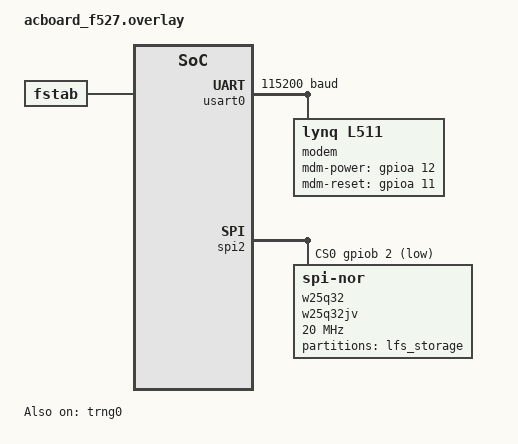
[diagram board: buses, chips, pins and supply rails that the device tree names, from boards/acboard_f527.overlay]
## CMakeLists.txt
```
cmake_minimum_required(VERSION 3.20.0)

find_package(Zephyr REQUIRED HINTS $ENV{ZEPHYR_BASE})
project(l511c_bringup LANGUAGES C CXX)

# === C sources ===
target_sources(app PRIVATE src/main.c)

# === C++ OCPP bridge ===
set_source_files_properties(src/ocpp_bridge.cpp PROPERTIES LANGUAGE CXX)
target_sources(app PRIVATE src/ocpp_bridge.cpp)

# === C++ STL headers (overrides picolibc's -nostdinc++) ===
# Zephyr SDK's full C++ STL is available but blocked by -nostdinc++
# We add the include paths explicitly for C++ files only
get_filename_component(GNU_BINDIR ${CMAKE_CXX_COMPILER} DIRECTORY)
get_filename_component(GNU_PREFIX ${GNU_BINDIR} DIRECTORY)
set(SDK_SYSROOT ${GNU_PREFIX}/arm-zephyr-eabi)
set(CXX_HEADER_ROOT ${SDK_SYSROOT}/include/c++/14.3.0)
# Target-specific C++ headers (c++config.h etc.)
execute_process(COMMAND ${CMAKE_CXX_COMPILER} -mcpu=cortex-m33 -mthumb -mfp16-format=ieee -print-multi-directory
  OUTPUT_VARIABLE MULTI_DIR OUTPUT_STRIP_TRAILING_WHITESPACE)
target_include_directories(app SYSTEM PRIVATE
  $<$<COMPILE_LANGUAGE:CXX>:${CXX_HEADER_ROOT}>
  $<$<COMPILE_LANGUAGE:CXX>:${CXX_HEADER_ROOT}/${MULTI_DIR}>
  $<$<COMPILE_LANGUAGE:CXX>:${CXX_HEADER_ROOT}/arm-zephyr-eabi/${MULTI_DIR}>
)

# Link C++ standard library (MicroOcpp needs std::string, new/delete, static ctors)
zephyr_link_libraries(stdc++ supc++)

# === MicroOcpp ===
file(GLOB_RECURSE MO_SOURCES
  ${CMAKE_CURRENT_SOURCE_DIR}/lib/MicroOcpp/src/*.cpp
  ${CMAKE_CURRENT_SOURCE_DIR}/lib/MicroOcpp/src/*.c
)
# Exclude files that need mbedTLS directly, or conflict with our adapter
list(FILTER MO_SOURCES EXCLUDE REGEX "FtpMbedTLS|CertificateMbedTLS|CertificateService|Platform\\.cpp")

foreach(src ${MO_SOURCES})
  set_source_files_properties(${src} PROPERTIES LANGUAGE CXX)
  target_sources(app PRIVATE ${src})
endforeach()

# === Include paths ===
target_include_directories(app PRIVATE
  ${CMAKE_CURRENT_SOURCE_DIR}/lib/MicroOcpp/src
  ${CMAKE_CURRENT_SOURCE_DIR}/lib/ArduinoJson/src
  ${CMAKE_CURRENT_SOURCE_DIR}/src
)

# === Build flags for MicroOcpp ===
target_compile_definitions(app PRIVATE
  MO_CUSTOM_WS
  MO_CUSTOM_CONSOLE
  MO_CUSTOM_TIMER
  MO_CUSTOM_RNG
  MO_PLATFORM=0
  MO_ENABLE_V201
  MO_OVERRIDE_ALLOCATION=1
  MO_CUSTOM_CONSOLE_MAXMSGSIZE=512
)
```

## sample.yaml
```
sample:
  description: ACBoard L511C WSS OCPP bring-up
  name: ACBoard L511C WSS OCPP bring-up
common:
  platform_allow:
    - acboard_f527
  tags:
    - modem
    - ocpp
    - websocket
tests:
  sample.boards.acboard.l511c_bringup:
    depends_on:
      - gpio
      - serial
    filter: dt_chosen_enabled("zephyr,modem-uart")
```

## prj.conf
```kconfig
# ============================================
# L511C OCPP on WSS (WebSocket Secure / TLS)
# GD32E513 + MicroOcpp + mbedTLS
# ============================================

# --- GPIO & Serial ---
CONFIG_GPIO=y
CONFIG_SERIAL=y
CONFIG_UART_INTERRUPT_DRIVEN=y
CONFIG_UART_ASYNC_API=y
CONFIG_CONSOLE=y
CONFIG_UART_CONSOLE=y
CONFIG_PRINTK=y

# --- Memory ---
CONFIG_HEAP_MEM_POOL_SIZE=24576
CONFIG_MAIN_STACK_SIZE=6144
CONFIG_SYSTEM_WORKQUEUE_STACK_SIZE=4096
CONFIG_NET_MGMT_EVENT_STACK_SIZE=2048

# --- Networking (native IP stack) ---
CONFIG_NETWORKING=y
CONFIG_NET_NATIVE=y
CONFIG_NET_IPV4=y
CONFIG_NET_IF_UNICAST_IPV4_ADDR_COUNT=2
CONFIG_NET_TCP=y
CONFIG_NET_UDP=y
CONFIG_NET_SOCKETS=y
CONFIG_DNS_RESOLVER=y
CONFIG_NET_SOCKETS_DNS_TIMEOUT=12000
CONFIG_NET_SOCKETS_CONNECT_TIMEOUT=15000
CONFIG_NET_CONTEXT_RCVTIMEO=y

# --- PPP L2 ---
CONFIG_NET_L2_PPP=y
CONFIG_NET_L2_PPP_OPTION_DNS_USE=y
CONFIG_NET_L2_PPP_PAP=y
CONFIG_NET_L2_PPP_PAP_USERNAME="cmnet"
CONFIG_NET_L2_PPP_PAP_PASSWORD="cmnet"
CONFIG_NET_L2_PPP_MGMT=y

# --- Modem (lynq,l511 driver powers the module and brings up PPP) ---
CONFIG_NET_MGMT=y
CONFIG_NET_MGMT_EVENT=y
CONFIG_NET_CONNECTION_MANAGER=y
CONFIG_MODEM_LYNQ_L511=y

# --- HTTP & WebSocket Client (WSS / TLS) ---
CONFIG_HTTP_CLIENT=y
CONFIG_WEBSOCKET_CLIENT=y
CONFIG_WEBSOCKET_MAX_CONTEXTS=1

# mbedTLS
CONFIG_MBEDTLS=y
CONFIG_MBEDTLS_ENABLE_HEAP=y
CONFIG_MBEDTLS_HEAP_SIZE=24576
CONFIG_MBEDTLS_SSL_IN_CONTENT_LEN=3072
CONFIG_MBEDTLS_SSL_OUT_CONTENT_LEN=3072
CONFIG_MBEDTLS_SSL_PROTO_TLS1_2=y
CONFIG_MBEDTLS_CIPHERSUITE_TLS_ECDHE_RSA_WITH_AES_128_GCM_SHA256=y
CONFIG_MBEDTLS_CIPHERSUITE_TLS_ECDHE_ECDSA_WITH_AES_128_GCM_SHA256=y
CONFIG_PSA_WANT_KEY_TYPE_RSA_PUBLIC_KEY=y
CONFIG_PSA_WANT_ALG_SHA_1=y

# TLS Socket (mTLS)
CONFIG_NET_SOCKETS_SOCKOPT_TLS=y
CONFIG_NET_SOCKETS_TLS_MAX_CONTEXTS=1
CONFIG_NET_SOCKETS_TLS_CERT_VERIFY_CALLBACK=y

# SNTP time sync (required for TLS cert verification)
CONFIG_SNTP=y

# --- Network buffers ---
CONFIG_NET_BUF_RX_COUNT=30
CONFIG_NET_BUF_TX_COUNT=30
CONFIG_NET_BUF_DATA_SIZE=256

# --- Logging (immediate mode, ERR only, enable net_sock_tls ERR) ---
CONFIG_LOG=y
CONFIG_NET_LOG=y
CONFIG_LOG_DEFAULT_LEVEL=1
CONFIG_LOG_MODE_IMMEDIATE=y
CONFIG_MODEM_LYNQ_L511_LOG_LEVEL_INF=y
CONFIG_NET_SOCKETS_LOG_LEVEL_ERR=y

# --- Random (GD32F527 hardware TRNG seeds a xoshiro PRNG) ---
CONFIG_ENTROPY_GENERATOR=y
CONFIG_ENTROPY_GD32_TRNG=y
CONFIG_XOSHIRO_RANDOM_GENERATOR=y

# --- POSIX ---
CONFIG_POSIX_API=y

# --- C++ support ---
CONFIG_CPP=y

# --- LittleFS filesystem (external SPI NOR flash) ---
CONFIG_SPI=y
CONFIG_SPI_GD32_DMA=y
CONFIG_SPI_NOR=y
CONFIG_FLASH=y
CONFIG_FLASH_MAP=y
CONFIG_FILE_SYSTEM=y
CONFIG_FILE_SYSTEM_LITTLEFS=y
CONFIG_FS_LITTLEFS_FMP_DEV=y
```

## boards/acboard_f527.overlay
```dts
/*
 * Copyright (c) 2026
 * SPDX-License-Identifier: Apache-2.0
 */

#include <zephyr/dt-bindings/gpio/gpio.h>
#include <zephyr/dt-bindings/dma/gd32_dma.h>

/ {
	fstab {
		compatible = "zephyr,fstab";
		lfs1: lfs1 {
			compatible = "zephyr,fstab,littlefs";
			mount-point = "/lfs1";
			partition = <&lfs_part>;
			automount;
			read-size = <256>;
			prog-size = <256>;
			cache-size = <256>;
			lookahead-size = <128>;
			block-cycles = <512>;
		};
	};
};

/* Hardware TRNG: entropy for mbedTLS / the network stack. */
&trng0 {
	status = "okay";
};

&usart0 {
	status = "okay";
	current-speed = <115200>;
	pinctrl-0 = <&usart0_default>;
	pinctrl-names = "default";
	dmas = <&dma1 2 4 GD32_DMA_PRIORITY_VERY_HIGH 3>,
	       <&dma1 7 4 GD32_DMA_PRIORITY_HIGH 3>;
	dma-names = "rx", "tx";

	modem: l511 {
		compatible = "lynq,l511";
		mdm-power-gpios = <&gpioa 12 GPIO_ACTIVE_HIGH>;
		mdm-reset-gpios = <&gpioa 11 GPIO_ACTIVE_HIGH>;
		reset-pulse-ms = <200>;
		at-ready-delay-ms = <5000>;
	};
};

&spi2 {
	status = "okay";
	cs-gpios = <&gpiob 2 GPIO_ACTIVE_LOW>;
	pinctrl-0 = <&spi2_default>;
	pinctrl-names = "default";
	dmas = <&dma0 2 0 GD32_DMA_PRIORITY_HIGH 3>,
	       <&dma0 5 0 GD32_DMA_PRIORITY_MEDIUM 3>;
	dma-names = "rx", "tx";

	w25q32: w25q32jv@0 {
		compatible = "jedec,spi-nor";
		reg = <0>;
		spi-max-frequency = <20000000>;
		jedec-id = [c8 40 16];
		size = <33554432>;
	};
};

&w25q32 {
	partitions {
		compatible = "fixed-partitions";
		#address-cells = <1>;
		#size-cells = <1>;
		lfs_part: partition@0 {
			label = "lfs_storage";
			reg = <0x00000000 0x00400000>;
		};
	};
};
```

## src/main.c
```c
/*
 * Copyright (c) 2026
 * SPDX-License-Identifier: Apache-2.0
 *
 * L511C OCPP over WSS (WebSocket Secure / TLS with mTLS) on ACBoard.
 *
 * The cellular modem bring-up (power, AT init, dial, PPP) is handled by the
 * lynq,l511 driver, which brings up the PPP network interface. This app waits
 * for connectivity, opens a mutually-authenticated TLS WebSocket to the OCPP
 * server, and hands the socket to the OCPP bridge.
 */

#include <errno.h>
#include <stdio.h>
#include <string.h>

#include <zephyr/device.h>
#include <zephyr/kernel.h>
#include <zephyr/net/net_event.h>
#include <zephyr/net/net_if.h>
#include <zephyr/net/net_ip.h>
#include <zephyr/net/net_mgmt.h>
#include <zephyr/net/ppp.h>
#include <zephyr/net/socket.h>
#include <zephyr/net/sntp.h>
#include <zephyr/net/tls_credentials.h>
#include <zephyr/net/websocket.h>
#include <zephyr/logging/log.h>

#include <mbedtls/x509.h>
#include <mbedtls/x509_crt.h>

#include "tls_certificates.h"
#include "ocpp_bridge.h"

LOG_MODULE_REGISTER(l511c, LOG_LEVEL_INF);

/* OCPP server (WSS / TLS) */
#define OCPP_SERVER_HOST  "47.111.208.192"
#define OCPP_SERVER_PORT  "6669"
#define OCPP_SERVER_PATH  "/ocppj/812345678"
#define OCPP_CHARGEBOX_ID "812345678"

/* WS temp buffer (used during handshake) */
#define WS_TEMP_BUF_LEN  1024

/* PPP / connectivity events */
#define PPP_EVENT_CONNECTED     BIT(0)
#define PPP_EVENT_DISCONNECTED  BIT(1)
#define PPP_EVENT_DNS_READY     BIT(2)

/* The lynq,l511 driver owns the modem and creates the PPP interface, which is
 * the only (default) network interface.
 */
#define CELL_IFACE net_if_get_default()
K_EVENT_DEFINE(ppp_events);

/* ===== Net mgmt handlers ===== */

static void l4_event_handler(uint64_t event, struct net_if *iface,
			     void *info, size_t info_length, void *user_data)
{
	ARG_UNUSED(info); ARG_UNUSED(info_length); ARG_UNUSED(user_data);
	if (iface != CELL_IFACE) { return; }
	switch (event) {
	case NET_EVENT_L4_CONNECTED:
		k_event_clear(&ppp_events, PPP_EVENT_DISCONNECTED);
		k_event_post(&ppp_events, PPP_EVENT_CONNECTED);
		break;
	case NET_EVENT_DNS_SERVER_ADD:
	case NET_EVENT_DNS_SERVERS_RECONFIGURED: k_event_post(&ppp_events, PPP_EVENT_DNS_READY); break;
	case NET_EVENT_L4_DISCONNECTED:
		k_event_clear(&ppp_events, PPP_EVENT_CONNECTED | PPP_EVENT_DNS_READY);
		k_event_post(&ppp_events, PPP_EVENT_DISCONNECTED);
		break;
	}
}
NET_MGMT_REGISTER_EVENT_HANDLER(ppp_l4, NET_EVENT_L4_CONNECTED |
	NET_EVENT_L4_DISCONNECTED | NET_EVENT_DNS_SERVER_ADD |
	NET_EVENT_DNS_SERVERS_RECONFIGURED, l4_event_handler, NULL);

static void ppp_event_handler(uint64_t event, struct net_if *iface,
			      void *info, size_t info_length, void *user_data)
{
	ARG_UNUSED(info); ARG_UNUSED(info_length); ARG_UNUSED(user_data);
	if (iface != CELL_IFACE) { return; }
	switch (event) {
	case NET_EVENT_PPP_PHASE_DEAD:   LOG_DBG("ppp: DEAD"); break;
	case NET_EVENT_PPP_PHASE_RUNNING: LOG_DBG("ppp: RUN"); break;
	case NET_EVENT_PPP_CARRIER_ON:   LOG_INF("ppp: carrier on"); break;
	case NET_EVENT_PPP_CARRIER_OFF:
		LOG_INF("ppp: carrier off");
		k_event_clear(&ppp_events, PPP_EVENT_CONNECTED | PPP_EVENT_DNS_READY);
		k_event_post(&ppp_events, PPP_EVENT_DISCONNECTED);
		break;
	}
}
NET_MGMT_REGISTER_EVENT_HANDLER(ppp_phase, NET_EVENT_PPP_PHASE_DEAD |
	NET_EVENT_PPP_PHASE_RUNNING | NET_EVENT_PPP_CARRIER_ON |
	NET_EVENT_PPP_CARRIER_OFF, ppp_event_handler, NULL);

/* ===== WSS connect (TLS + mTLS) ===== */

/* TLS verify callback: skip CN/SAN hostname check since server cert has no CN */
static int tls_verify_cb(void *data, mbedtls_x509_crt *crt, int depth, uint32_t *flags)
{
	ARG_UNUSED(data); ARG_UNUSED(crt); ARG_UNUSED(depth);
	*flags &= ~MBEDTLS_X509_BADCERT_CN_MISMATCH;
	return 0;
}

static uint8_t ws_temp_buf[WS_TEMP_BUF_LEN];

static int tls_credential_add_once(sec_tag_t tag,
				   enum tls_credential_type type,
				   const void *cred, size_t credlen)
{
	int ret = tls_credential_add(tag, type, cred, credlen);

	return ret == -EEXIST ? 0 : ret;
}

static int ws_connect(void)
{
	struct zsock_addrinfo hints = { .ai_family = AF_INET, .ai_socktype = SOCK_STREAM };
	struct zsock_addrinfo *ai = NULL;
	struct sockaddr_in peer = {0};
	struct websocket_request req;
	char addr[NET_IPV4_ADDR_LEN];
	sec_tag_t sec_tags[] = { CA_CERTIFICATE_TAG, CLIENT_CERT_TAG };
	int sock = -1, ws_fd = -1, ret;

	/* Register certificates for mTLS */
	ret = tls_credential_add_once(CA_CERTIFICATE_TAG, TLS_CREDENTIAL_CA_CERTIFICATE,
				      ca_certificate, sizeof(ca_certificate));
	if (ret < 0) { LOG_ERR("CA cert add err: %d", ret); return ret; }
	LOG_DBG("CA cert ok (tag=%d)", CA_CERTIFICATE_TAG);

	ret = tls_credential_add_once(CLIENT_CERT_TAG, TLS_CREDENTIAL_PUBLIC_CERTIFICATE,
				      client_certificate, sizeof(client_certificate));
	if (ret < 0) { LOG_ERR("Client cert add err: %d", ret); return ret; }

	ret = tls_credential_add_once(CLIENT_CERT_TAG, TLS_CREDENTIAL_PRIVATE_KEY,
				      client_private_key, sizeof(client_private_key));
	if (ret < 0) { LOG_ERR("Client key add err: %d", ret); return ret; }
	LOG_DBG("Client cert+key ok (tag=%d)", CLIENT_CERT_TAG);

	/* Sync time for cert validity check */
	{
		struct sntp_time sntp_ts;
		struct timespec ts;
		LOG_DBG("SNTP ...");
		ret = sntp_simple("203.107.6.88", 5000, &sntp_ts);
		if (ret < 0) { ret = sntp_simple("ntp.aliyun.com", 8000, &sntp_ts); }
		if (ret >= 0) {
			ts.tv_sec = (time_t)sntp_ts.seconds; ts.tv_nsec = 0;
			clock_settime(CLOCK_REALTIME, &ts);
			LOG_DBG("SNTP ok");
		} else {
			/* Fallback: June 8, 2026 */
			ts.tv_sec = 1780876800; ts.tv_nsec = 0;
			clock_settime(CLOCK_REALTIME, &ts);
			LOG_WRN("SNTP fail (%d), using hardcoded time", ret);
		}
	}

	/* DNS resolve */
	LOG_DBG("resolve %s:%s", OCPP_SERVER_HOST, OCPP_SERVER_PORT);
	ret = zsock_getaddrinfo(OCPP_SERVER_HOST, OCPP_SERVER_PORT, &hints, &ai);
	if (ret != 0 || !ai) { ret = -ENOENT; goto out; }
	memcpy(&peer, ai->ai_addr, sizeof(peer));
	zsock_freeaddrinfo(ai); ai = NULL;
	zsock_inet_ntop(AF_INET, &peer.sin_addr, addr, sizeof(addr));
	LOG_DBG("-> %s:%u", addr, ntohs(peer.sin_port));

	/* Test plain TCP connectivity first */
	LOG_DBG("TCP test to %s:%u ...", addr, ntohs(peer.sin_port));
	{
		int tsock = zsock_socket(AF_INET, SOCK_STREAM, IPPROTO_TCP);
		if (tsock >= 0) {
			struct timeval tv = {.tv_sec = 10};
			zsock_setsockopt(tsock, SOL_SOCKET, SO_SNDTIMEO, &tv, sizeof(tv));
			int tret = zsock_connect(tsock, (struct sockaddr *)&peer, sizeof(peer));
			if (tret < 0) {
				LOG_WRN("TCP test fail: %d", -errno);
			} else {
				LOG_DBG("TCP test ok (SYN reached server)");
			}
			zsock_close(tsock);
		} else {
			LOG_WRN("TCP test socket create fail: %d", -errno);
		}
	}

	/* TLS socket — mutual auth: verify server cert, skip hostname check */
	sock = zsock_socket(AF_INET, SOCK_STREAM, IPPROTO_TLS_1_2);
	if (sock < 0) {
		ret = -errno;
		LOG_ERR("TLS socket err: %d", ret);
		goto out;
	}

	zsock_setsockopt(sock, SOL_TLS, TLS_SEC_TAG_LIST, sec_tags, sizeof(sec_tags));
	{
		int verify_req = TLS_PEER_VERIFY_REQUIRED;
		zsock_setsockopt(sock, SOL_TLS, TLS_PEER_VERIFY,
				 &verify_req, sizeof(verify_req));
	}
	/* Set hostname to prevent Zephyr's forced empty-string verification.
	 * Custom verify callback strips CN_MISMATCH — server cert has no CN,
	 * so hostname check against IP would always fail.
	 */
	zsock_setsockopt(sock, SOL_TLS, TLS_HOSTNAME,
			 OCPP_SERVER_HOST, sizeof(OCPP_SERVER_HOST) - 1);
	{
		struct zsock_tls_cert_verify_cb vfy_cb = {
			.cb = tls_verify_cb,
			.ctx = NULL,
		};
		zsock_setsockopt(sock, SOL_TLS, TLS_CERT_VERIFY_CALLBACK,
				 &vfy_cb, sizeof(vfy_cb));
	}
	{
		struct timeval tv = {.tv_sec = 15};
		zsock_setsockopt(sock, SOL_SOCKET, SO_RCVTIMEO, &tv, sizeof(tv));
		zsock_setsockopt(sock, SOL_SOCKET, SO_SNDTIMEO, &tv, sizeof(tv));
	}

	LOG_DBG("TLS connecting ...");
	ret = zsock_connect(sock, (struct sockaddr *)&peer, sizeof(peer));
	if (ret < 0) { LOG_ERR("TLS connect err: %d", -errno); ret = -errno; goto out; }
	LOG_INF("TLS ok");

	/* WebSocket upgrade over TLS */
	const char *ocpp_headers[] = {
		"Sec-WebSocket-Protocol: ocpp2.0\r\n",
		NULL
	};
	memset(&req, 0, sizeof(req));
	req.host = OCPP_SERVER_HOST; req.url = OCPP_SERVER_PATH;
	req.optional_headers = ocpp_headers;
	req.tmp_buf = ws_temp_buf; req.tmp_buf_len = sizeof(ws_temp_buf);
	ws_fd = websocket_connect(sock, &req, 15000, NULL);
	if (ws_fd < 0) { LOG_ERR("ws upgrade err: %d", ws_fd); ret = ws_fd; goto out; }
	LOG_INF("WSS ok (fd=%d)", ws_fd);
	return ws_fd;

out:
	if (ws_fd >= 0) { websocket_disconnect(ws_fd); }
	if (sock >= 0)  { zsock_close(sock); }
	if (ai) { zsock_freeaddrinfo(ai); }
	return ret;
}

static bool cellular_ready(void)
{
	struct net_if *iface = CELL_IFACE;

	return iface != NULL && net_if_is_up(iface) &&
	       net_if_is_carrier_ok(iface) && !net_if_is_dormant(iface);
}

static int wait_for_ppp_link(void)
{
	LOG_INF("waiting for cellular PPP link (driver brings it up) ...");

	if (cellular_ready()) {
		k_event_post(&ppp_events, PPP_EVENT_CONNECTED);
		return 0;
	}

	if ((k_event_wait(&ppp_events, PPP_EVENT_CONNECTED, false, K_SECONDS(180)) &
	     PPP_EVENT_CONNECTED) == 0) {
		LOG_ERR("PPP timeout");
		return -ETIMEDOUT;
	}

	return 0;
}

/* ===== Main ===== */

int main(void)
{
	LOG_INF("=== L511C OCPP on WSS ===");

	while (1) {
		if (wait_for_ppp_link() < 0) {
			k_msleep(5000);
			continue;
		}

		LOG_INF("PPP ok");
		if ((k_event_wait(&ppp_events, PPP_EVENT_DNS_READY, false, K_SECONDS(2)) &
		     PPP_EVENT_DNS_READY) == 0) {
			LOG_DBG("DNS not ready yet, continue with IP endpoint");
		}
		k_msleep(200);

		int ws_fd = ws_connect();
		if (ws_fd < 0) {
			LOG_ERR("WS fail: %d", ws_fd);
			k_msleep(5000);
			continue;
		}

		LOG_INF("OCPP bridge start ...");
		int ret = ocpp_bridge_run(ws_fd, OCPP_SERVER_HOST, OCPP_CHARGEBOX_ID);
		LOG_WRN("OCPP bridge stopped: %d", ret);
		k_msleep(5000);
	}
}
```

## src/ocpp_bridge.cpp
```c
/*
 * OCPP Bridge — Zephyr WebSocket adapter for MicroOcpp
 * SPDX-License-Identifier: Apache-2.0
 */

extern "C" {
#include <zephyr/kernel.h>
#include <zephyr/device.h>
#include <zephyr/devicetree.h>
#include <zephyr/drivers/uart.h>
#include <zephyr/fs/fs.h>
#include <zephyr/net/websocket.h>
#include <stdio.h>
#include <string.h>
}

#include <zephyr/logging/log.h>

#include <functional>
#include <memory>
#include <string>
#include <MicroOcpp.h>
#include <MicroOcpp/Core/Connection.h>
#include <MicroOcpp/Core/FilesystemAdapter.h>

LOG_MODULE_REGISTER(ocpp, LOG_LEVEL_INF);

/* MicroOcpp files are stored under this mount point */
#define MO_FS_PREFIX "/lfs1/"

/* ===== MO_CUSTOM_CONSOLE ===== */

char _mo_console_msg_buf[MO_CUSTOM_CONSOLE_MAXMSGSIZE];
extern "C" void _mo_console_out(const char *msg) {
	/* Show all messages during bringup */
	static const struct device *uart;
	if (!uart) { uart = DEVICE_DT_GET(DT_CHOSEN(zephyr_console)); }
	for (const char *p = msg; *p && *p != '\n'; p++) {
		uart_poll_out(uart, *p);
	}
	uart_poll_out(uart, '\r');
	uart_poll_out(uart, '\n');
}

/* ===== MO_CUSTOM_TIMER ===== */

static unsigned long (*mo_tick_fn)() = nullptr;
extern "C" void mocpp_set_timer(unsigned long (*get_ms)()) { mo_tick_fn = get_ms; }
extern "C" unsigned long mocpp_tick_ms_custom() {
	return mo_tick_fn ? mo_tick_fn() : (unsigned long)k_uptime_get();
}

/* ===== MO_CUSTOM_RNG ===== */
static uint32_t mo_rng_seed = 12345;
extern "C" uint32_t mocpp_rng_custom() {
	mo_rng_seed = mo_rng_seed * 1103515245 + 12345;
	return mo_rng_seed;
}

/* ===== Filesystem adapter (LittleFS on SPI NOR flash) ===== */

static std::string mo_full_path(const char *path)
{
	return std::string(MO_FS_PREFIX) + path;
}

class ZephyrFileAdapter : public MicroOcpp::FileAdapter {
public:
	ZephyrFileAdapter(const char *path, const char *mode)
	{
		fs_file_t_init(&file_);

		fs_mode_t flags = FS_O_CREATE;
		if (strchr(mode, 'w')) {
			flags = FS_O_CREATE | FS_O_WRITE | FS_O_TRUNC;
		} else if (strchr(mode, 'a')) {
			flags = FS_O_CREATE | FS_O_WRITE | FS_O_APPEND;
		} else {
			flags = FS_O_READ;
		}
		if (strchr(mode, '+')) {
			flags |= FS_O_RDWR;
		}

		int ret = fs_open(&file_, path, flags);
		if (ret < 0) {
			LOG_ERR("fs: open(%s) err %d", path, ret);
			valid_ = false;
		} else {
			valid_ = true;
		}
	}

	~ZephyrFileAdapter() override
	{
		if (valid_) {
			fs_close(&file_);
		}
	}

	size_t read(char *buf, size_t len) override
	{
		if (!valid_) { return 0; }
		ssize_t ret = fs_read(&file_, buf, len);
		return ret > 0 ? (size_t)ret : 0;
	}

	size_t write(const char *buf, size_t len) override
	{
		if (!valid_) { return 0; }
		ssize_t ret = fs_write(&file_, buf, len);
		return ret > 0 ? (size_t)ret : 0;
	}

	size_t seek(size_t offset) override
	{
		if (!valid_) { return 0; }
		int ret = fs_seek(&file_, (off_t)offset, FS_SEEK_SET);
		if (ret < 0) { return 0; }
		return (size_t)fs_tell(&file_);
	}

	int read() override
	{
		if (!valid_) { return -1; }
		unsigned char c;
		ssize_t ret = fs_read(&file_, &c, 1);
		return ret == 1 ? (int)c : -1;
	}

	bool isValid() const { return valid_; }

private:
	struct fs_file_t file_;
	bool valid_ = false;
};

class ZephyrFS : public MicroOcpp::FilesystemAdapter {
public:
	int stat(const char *path, size_t *size) override
	{
		struct fs_dirent entry;
		std::string full = mo_full_path(path);
		int ret = fs_stat(full.c_str(), &entry);
		if (ret < 0) { return ret; }
		if (size) { *size = entry.size; }
		return 0;
	}

	std::unique_ptr<MicroOcpp::FileAdapter> open(const char *fn, const char *mode) override
	{
		std::string full = mo_full_path(fn);
		auto adapter = std::unique_ptr<ZephyrFileAdapter>(
			new ZephyrFileAdapter(full.c_str(), mode));
		if (!adapter->isValid()) {
			return nullptr;
		}
		return adapter;
	}

	bool remove(const char *fn) override
	{
		std::string full = mo_full_path(fn);
		int ret = fs_unlink(full.c_str());
		return ret == 0;
	}

	int ftw_root(std::function<int(const char *fpath)> fn) override
	{
		struct fs_dir_t dir;
		fs_dir_t_init(&dir);
		int count = 0;

		int ret = fs_opendir(&dir, MO_FS_PREFIX);
		if (ret < 0) {
			LOG_ERR("fs: opendir(%s) err %d", MO_FS_PREFIX, ret);
			return ret;  /* non-zero = error, as MO expects */
		}

		struct fs_dirent entry;
		while (fs_readdir(&dir, &entry) == 0) {
			if (entry.name[0] == '\0') { break; }
			if (entry.type == FS_DIR_ENTRY_DIR) { continue; }
			count++;
			fn(entry.name);
		}
		fs_closedir(&dir);

		/* MO expects 0 = success */
		return 0;
	}
};

/* ===== Zephyr WS Connection ===== */

class ZephyrWSConnection : public MicroOcpp::Connection {
public:
	ZephyrWSConnection(int ws_fd) : ws_fd_(ws_fd) {}

	void loop() override {
		uint8_t buf[1024];
		uint64_t remaining = UINT64_MAX;
		uint32_t msg_type = 0;
		int ret = websocket_recv_msg(ws_fd_, buf, sizeof(buf)-1,
					     &msg_type, &remaining, 0);
		if (ret > 0) {
			if (msg_type & WEBSOCKET_FLAG_CLOSE) {
				LOG_INF("ws close");
				last_error_ = 0;
				connected_ = false;
				return;
			}
			if (msg_type & WEBSOCKET_FLAG_PING) {
				ret = websocket_send_msg(ws_fd_, nullptr, 0,
							 WEBSOCKET_OPCODE_PONG, true, true, 1000);
				if (ret < 0) {
					LOG_WRN("ws pong err %d", ret);
					last_error_ = ret;
					connected_ = false;
				}
				return;
			}
			if (msg_type & (WEBSOCKET_FLAG_TEXT | WEBSOCKET_FLAG_BINARY)) {
				buf[ret] = '\0';
				LOG_DBG("OCPP<- %.*s%s", (ret > 256 ? 256 : ret),
					(const char *)buf, ret > 256 ? "..." : "");
				if (recv_cb_) { recv_cb_((const char *)buf, (size_t)ret); }
			}
		} else if (ret == -EAGAIN) {
		} else if (ret == 0 || ret == -ENOTCONN) {
			last_error_ = ret;
			connected_ = false;
		} else if (ret < 0) {
			LOG_WRN("ws err %d", ret);
			last_error_ = ret;
			connected_ = false;
		}
	}

	bool sendTXT(const char *msg, size_t length) override {
		LOG_DBG("OCPP-> %.*s%s", ((int)length > 256 ? 256 : (int)length),
			msg, length > 256 ? "..." : "");
		int ret = websocket_send_msg(ws_fd_, (const uint8_t *)msg, length,
					     WEBSOCKET_OPCODE_DATA_TEXT, true, true, 3000);
		if (ret < 0) {
			LOG_WRN("ws send err %d", ret);
			last_error_ = ret;
			connected_ = false;
		}
		return ret > 0;
	}

	void setReceiveTXTcallback(MicroOcpp::ReceiveTXTcallback &cb) override { recv_cb_ = cb; }
	unsigned long getLastConnected() override { return last_connected_; }
	bool isConnected() override { return connected_; }
	void setConnected(bool c) { connected_ = c; last_connected_ = k_uptime_get(); }
	int lastError() const { return last_error_; }

private:
	int ws_fd_;
	bool connected_ = true;
	int last_error_ = 0;
	unsigned long last_connected_ = 0;
	MicroOcpp::ReceiveTXTcallback recv_cb_;
};

/* ===== Print MO config at boot ===== */

static void print_mo_config(void)
{
	struct fs_dir_t dir;
	struct fs_dirent entry;
	char buf[256];

	fs_dir_t_init(&dir);

	int ret = fs_opendir(&dir, MO_FS_PREFIX);
	if (ret < 0) {
		LOG_DBG("MO config: opendir err %d", ret);
		return;
	}

	LOG_DBG("MO config on flash (mount: %s)", MO_FS_PREFIX);

	while (fs_readdir(&dir, &entry) == 0) {
		if (entry.name[0] == '\0') { break; }
		if (entry.type == FS_DIR_ENTRY_DIR) { continue; }

		LOG_DBG("  [%s] (%u bytes)", entry.name, (unsigned)entry.size);

		/* Read and print file content (up to 240 chars) */
		struct fs_file_t file;
		fs_file_t_init(&file);
		char fpath[260];
		snprintf(fpath, sizeof(fpath), "%s%s", MO_FS_PREFIX, entry.name);
		ret = fs_open(&file, fpath, FS_O_READ);
		if (ret == 0) {
			ssize_t n = fs_read(&file, buf, sizeof(buf) - 1);
			if (n > 0) {
				buf[n] = '\0';
				LOG_DBG("    %.*s%s",
					(n > 240 ? 240 : (int)n), buf,
					n > 240 ? "..." : "");
			}
			fs_close(&file);
		}
	}

	fs_closedir(&dir);

	/* FS usage */
	struct fs_statvfs st;
	if (fs_statvfs(MO_FS_PREFIX, &st) == 0) {
		unsigned long total_kb = (st.f_blocks * st.f_frsize) / 1024;
		unsigned long free_kb  = (st.f_bfree * st.f_frsize) / 1024;
		LOG_DBG("  [FS] %lu / %lu KB used", total_kb - free_kb, total_kb);
	}
}

/* ===== Entry point ===== */

extern "C" int ocpp_bridge_run(int ws_fd, const char *server_host,
				const char *charge_box_id)
{
	ARG_UNUSED(server_host);
	LOG_INF("init box=%s", charge_box_id);

	ZephyrWSConnection conn(ws_fd);
	conn.setConnected(true);
	static ZephyrFS fs;
	static bool config_dumped;

	/* Route MO allocations via Zephyr heap (coalescing, less fragmentation) */
	mo_mem_set_malloc_free(
		[](size_t sz) -> void* { return k_malloc(sz); },
		[](void* p) { k_free(p); }
	);

	mocpp_initialize(conn,
		ChargerCredentials::v201("H1", "CAMS", "V1.1.1", "812345678"),
		std::shared_ptr<MicroOcpp::FilesystemAdapter>(&fs, [](MicroOcpp::FilesystemAdapter* p){}),
		false,
		MicroOcpp::ProtocolVersion(2, 0, 1));

	LOG_INF("running");

	if (!config_dumped) {
		print_mo_config();
		config_dumped = true;
	}

	while (conn.isConnected()) {
		mocpp_loop();
		if (conn.isConnected()) {
			conn.loop();
		}
		k_msleep(10);
	}

	int ret = conn.lastError();
	LOG_INF("stopped (%d)", ret);
	mocpp_deinitialize();
	websocket_unregister(ws_fd);

	return ret < 0 ? ret : -ENOTCONN;
}
```

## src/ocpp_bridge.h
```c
/*
 * OCPP Bridge - C interface to MicroOcpp C++ adapter
 * SPDX-License-Identifier: Apache-2.0
 */
#ifndef OCPP_BRIDGE_H
#define OCPP_BRIDGE_H

#ifdef __cplusplus
extern "C" {
#endif

/** Run the OCPP stack until the WebSocket disconnects or fails. */
int ocpp_bridge_run(int ws_fd, const char *server_host, const char *charge_box_id);

#ifdef __cplusplus
}
#endif

#endif
```

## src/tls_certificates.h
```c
/*
 * Copyright (c) 2026
 * SPDX-License-Identifier: Apache-2.0
 *
 * TLS Certificates for WSS mutual authentication (mTLS)
 * All in DER format
 *
 * CA certificate:   serverRootCA.crt — CAMS root CA (to verify server)
 * Client cert:      client_new.crt — signed by ca_rsa (for client auth)
 * Client key:       client.key — RSA 2048-bit private key
 */

#ifndef TLS_CERTIFICATES_H
#define TLS_CERTIFICATES_H

#define CA_CERTIFICATE_TAG  1
#define CLIENT_CERT_TAG     2

/* === CA Certificate (CAMS root CA — serverRootCA.crt) === */
static const unsigned char ca_certificate[] = {
0x30, 0x82, 0x03, 0xe1, 0x30, 0x82, 0x02, 0xc9, 0xa0, 0x03, 0x02, 0x01,
0x02, 0x02, 0x09, 0x00, 0x9b, 0x49, 0x7f, 0xe2, 0x07, 0x21, 0x9a, 0x0c,
0x30, 0x0d, 0x06, 0x09, 0x2a, 0x86, 0x48, 0x86, 0xf7, 0x0d, 0x01, 0x01,
0x0b, 0x05, 0x00, 0x30, 0x81, 0x86, 0x31, 0x0b, 0x30, 0x09, 0x06, 0x03,
0x55, 0x04, 0x06, 0x13, 0x02, 0x43, 0x4e, 0x31, 0x10, 0x30, 0x0e, 0x06,
0x03, 0x55, 0x04, 0x08, 0x0c, 0x07, 0x4a, 0x69, 0x61, 0x6e, 0x67, 0x53,
0x75, 0x31, 0x12, 0x30, 0x10, 0x06, 0x03, 0x55, 0x04, 0x07, 0x0c, 0x09,
0x43, 0x68, 0x61, 0x6e, 0x67, 0x5a, 0x68, 0x6f, 0x75, 0x31, 0x2d, 0x30,
0x2b, 0x06, 0x03, 0x55, 0x04, 0x0a, 0x0c, 0x24, 0x43, 0x41, 0x4d, 0x53,
0x20, 0x4e, 0x65, 0x77, 0x20, 0x45, 0x6e, 0x65, 0x72, 0x67, 0x79, 0x20,
0x54, 0x65, 0x63, 0x68, 0x6e, 0x6f, 0x6c, 0x6f, 0x67, 0x79, 0x20, 0x43,
0x6f, 0x2e, 0x2c, 0x20, 0x4c, 0x74, 0x64, 0x2e, 0x31, 0x22, 0x30, 0x20,
0x06, 0x03, 0x55, 0x04, 0x0b, 0x0c, 0x19, 0x50, 0x72, 0x6f, 0x64, 0x75,
0x63, 0x74, 0x20, 0x44, 0x65, 0x76, 0x65, 0x6c, 0x6f, 0x70, 0x6d, 0x65,
0x6e, 0x74, 0x20, 0x44, 0x65, 0x70, 0x74, 0x2e, 0x30, 0x1e, 0x17, 0x0d,
0x32, 0x31, 0x30, 0x34, 0x30, 0x32, 0x30, 0x36, 0x31, 0x32, 0x32, 0x37,
0x5a, 0x17, 0x0d, 0x34, 0x33, 0x30, 0x39, 0x32, 0x36, 0x30, 0x36, 0x31,
0x32, 0x32, 0x37, 0x5a, 0x30, 0x81, 0x86, 0x31, 0x0b, 0x30, 0x09, 0x06,
0x03, 0x55, 0x04, 0x06, 0x13, 0x02, 0x43, 0x4e, 0x31, 0x10, 0x30, 0x0e,
0x06, 0x03, 0x55, 0x04, 0x08, 0x0c, 0x07, 0x4a, 0x69, 0x61, 0x6e, 0x67,
0x53, 0x75, 0x31, 0x12, 0x30, 0x10, 0x06, 0x03, 0x55, 0x04, 0x07, 0x0c,
0x09, 0x43, 0x68, 0x61, 0x6e, 0x67, 0x5a, 0x68, 0x6f, 0x75, 0x31, 0x2d,
0x30, 0x2b, 0x06, 0x03, 0x55, 0x04, 0x0a, 0x0c, 0x24, 0x43, 0x41, 0x4d,
0x53, 0x20, 0x4e, 0x65, 0x77, 0x20, 0x45, 0x6e, 0x65, 0x72, 0x67, 0x79,
0x20, 0x54, 0x65, 0x63, 0x68, 0x6e, 0x6f, 0x6c, 0x6f, 0x67, 0x79, 0x20,
0x43, 0x6f, 0x2e, 0x2c, 0x20, 0x4c, 0x74, 0x64, 0x2e, 0x31, 0x22, 0x30,
0x20, 0x06, 0x03, 0x55, 0x04, 0x0b, 0x0c, 0x19, 0x50, 0x72, 0x6f, 0x64,
0x75, 0x63, 0x74, 0x20, 0x44, 0x65, 0x76, 0x65, 0x6c, 0x6f, 0x70, 0x6d,
0x65, 0x6e, 0x74, 0x20, 0x44, 0x65, 0x70, 0x74, 0x2e, 0x30, 0x82, 0x01,
0x22, 0x30, 0x0d, 0x06, 0x09, 0x2a, 0x86, 0x48, 0x86, 0xf7, 0x0d, 0x01,
0x01, 0x01, 0x05, 0x00, 0x03, 0x82, 0x01, 0x0f, 0x00, 0x30, 0x82, 0x01,
0x0a, 0x02, 0x82, 0x01, 0x01, 0x00, 0xb7, 0x7c, 0xc2, 0x21, 0xff, 0x7c,
0xec, 0x03, 0x4e, 0x52, 0xb8, 0xc3, 0x9e, 0xc0, 0x92, 0x17, 0x09, 0x20,
0xf9, 0x3a, 0x51, 0x15, 0x9c, 0xc0, 0x13, 0xda, 0xe8, 0x8e, 0xb4, 0x91,
0x74, 0xfa, 0x3d, 0xa4, 0xd4, 0x1b, 0xb7, 0x36, 0x77, 0x34, 0xa7, 0xed,
0x10, 0x3b, 0x57, 0x3f, 0x63, 0xc2, 0x29, 0x16, 0xb1, 0xca, 0x3e, 0x62,
0x0a, 0xe2, 0x69, 0x01, 0x3e, 0x37, 0xd1, 0xde, 0x78, 0xcf, 0x73, 0x85,
0x9b, 0xfe, 0xd9, 0x99, 0x68, 0x6b, 0xe8, 0x7e, 0x5a, 0x06, 0xbf, 0x43,
0xc6, 0xd7, 0x69, 0x9b, 0x0d, 0x65, 0x16, 0x3f, 0x6b, 0x8a, 0xdb, 0x9c,
0x0c, 0xf3, 0x05, 0x9d, 0xe7, 0xd5, 0xa9, 0x34, 0x49, 0xd4, 0xd8, 0x5a,
0x7e, 0x82, 0x22, 0x49, 0xd6, 0x28, 0x5e, 0x6b, 0xe6, 0xcf, 0x10, 0x23,
0x3a, 0x58, 0xf3, 0x8b, 0x65, 0xb8, 0x81, 0x56, 0x86, 0x9e, 0x94, 0xa0,
0xcb, 0x0f, 0x19, 0x37, 0xb6, 0x3b, 0xbe, 0x8d, 0x68, 0x4f, 0xf4, 0x9d,
0xb8, 0x09, 0xea, 0xd3, 0x04, 0xdd, 0x68, 0x6c, 0x0b, 0xc2, 0xca, 0x20,
0x43, 0x77, 0x70, 0xee, 0x64, 0x91, 0x5d, 0xc1, 0xd2, 0xd4, 0x1a, 0x28,
0x6f, 0xe8, 0x83, 0x07, 0x27, 0x6e, 0xc5, 0x6d, 0x90, 0x4d, 0xf5, 0x96,
0x4b, 0xad, 0x75, 0xc7, 0xfb, 0xb8, 0x2e, 0xfd, 0xed, 0x65, 0x45, 0x5c,
0x90, 0x86, 0x76, 0xdc, 0xf1, 0xfc, 0xfe, 0xb6, 0xd5, 0x4b, 0x85, 0x79,
0xad, 0x8c, 0x2e, 0xde, 0x87, 0x1f, 0xfa, 0x46, 0x9c, 0x43, 0xac, 0xf5,
0x0a, 0xce, 0x9c, 0xdb, 0x51, 0x4c, 0xf8, 0x10, 0x24, 0xb5, 0xf1, 0x31,
0x69, 0x53, 0x4c, 0x1a, 0x97, 0x7e, 0x3b, 0x54, 0xfb, 0xde, 0xfb, 0x64,
0xce, 0xd6, 0x81, 0x87, 0xc1, 0x26, 0xed, 0x33, 0xa0, 0x0d, 0x6b, 0x46,
0x09, 0x25, 0x8e, 0x41, 0xdb, 0xb4, 0x97, 0x8a, 0xc5, 0xbd, 0x02, 0x03,
0x01, 0x00, 0x01, 0xa3, 0x50, 0x30, 0x4e, 0x30, 0x1d, 0x06, 0x03, 0x55,
0x1d, 0x0e, 0x04, 0x16, 0x04, 0x14, 0x15, 0x12, 0x08, 0xea, 0x06, 0x74,
0x67, 0xbd, 0x48, 0x9a, 0xec, 0xd1, 0x6f, 0xbb, 0xfa, 0x72, 0x4d, 0x1f,
0xc2, 0xd6, 0x30, 0x1f, 0x06, 0x03, 0x55, 0x1d, 0x23, 0x04, 0x18, 0x30,
0x16, 0x80, 0x14, 0x15, 0x12, 0x08, 0xea, 0x06, 0x74, 0x67, 0xbd, 0x48,
0x9a, 0xec, 0xd1, 0x6f, 0xbb, 0xfa, 0x72, 0x4d, 0x1f, 0xc2, 0xd6, 0x30,
0x0c, 0x06, 0x03, 0x55, 0x1d, 0x13, 0x04, 0x05, 0x30, 0x03, 0x01, 0x01,
0xff, 0x30, 0x0d, 0x06, 0x09, 0x2a, 0x86, 0x48, 0x86, 0xf7, 0x0d, 0x01,
0x01, 0x0b, 0x05, 0x00, 0x03, 0x82, 0x01, 0x01, 0x00, 0x25, 0x23, 0x43,
0xce, 0xbc, 0x86, 0x91, 0x74, 0xc1, 0x50, 0x34, 0x9d, 0x27, 0x9c, 0x24,
0x7f, 0xf7, 0x18, 0xe9, 0x9e, 0x96, 0xed, 0xbb, 0xed, 0xba, 0x14, 0x7b,
0x12, 0x47, 0x40, 0x09, 0xed, 0x25, 0x75, 0x41, 0x4b, 0x94, 0xb3, 0x0f,
0x5b, 0x48, 0xc3, 0x48, 0xd7, 0xbe, 0x24, 0xf1, 0x95, 0x93, 0xc9, 0x4e,
0xb4, 0xa7, 0xf1, 0x2f, 0x89, 0x66, 0xcb, 0x0d, 0xad, 0xa4, 0x7f, 0x30,
0x12, 0xb0, 0xda, 0x0d, 0x78, 0x28, 0x94, 0x9b, 0x09, 0xd6, 0xaf, 0x00,
0xc1, 0x0f, 0xab, 0x50, 0x02, 0xab, 0x38, 0x38, 0x82, 0xc7, 0xc3, 0xdc,
0xdd, 0x1e, 0xac, 0x7a, 0xe7, 0x33, 0xc4, 0xa9, 0xc4, 0x20, 0xba, 0x10,
0x2d, 0x69, 0x32, 0x6e, 0xff, 0xb8, 0xe4, 0x4c, 0xe9, 0xf8, 0x77, 0x4b,
0x66, 0x17, 0x61, 0x27, 0xaf, 0xa5, 0x60, 0xd6, 0x42, 0x06, 0x5a, 0xcc,
0xd7, 0x13, 0xf5, 0x5b, 0xd0, 0x1f, 0x7f, 0x7d, 0xc6, 0x53, 0x76, 0x3d,
0x67, 0xb3, 0xc5, 0x45, 0x8e, 0xbf, 0xa9, 0xcd, 0x96, 0x6d, 0xe9, 0xf9,
0xf2, 0x3d, 0xb6, 0x7d, 0x66, 0x89, 0xbe, 0xfd, 0x93, 0x7f, 0x35, 0x23,
0x3a, 0xc1, 0x20, 0x6d, 0xc2, 0x89, 0xc5, 0x34, 0x34, 0x5e, 0x09, 0x7d,
0x2d, 0x18, 0xc9, 0x6c, 0xe9, 0xe0, 0x3b, 0x5d, 0x36, 0xbc, 0xc9, 0xbc,
0xf4, 0x57, 0x05, 0x96, 0x5c, 0xfa, 0xc0, 0xb8, 0xbc, 0x62, 0x43, 0x0f,
0x23, 0x0b, 0x12, 0x1d, 0xdf, 0xe4, 0xe0, 0xf9, 0xde, 0x12, 0x3e, 0xef,
0x3f, 0x76, 0xc8, 0xbe, 0x83, 0x44, 0x58, 0x62, 0xfe, 0xed, 0x89, 0x92,
0x92, 0x83, 0xfa, 0x40, 0x00, 0x0a, 0xa9, 0xb6, 0x36, 0xb7, 0xe0, 0x80,
0xf5, 0xb0, 0x63, 0x5f, 0xa0, 0x15, 0xdb, 0x60, 0x86, 0x61, 0xc4, 0x1f,
0xc3, 0x9e, 0xb8, 0x2a, 0xe4, 0xd4, 0x27, 0xbe, 0x56, 0xf2, 0x2b, 0xf6,
0x39
};

/* === Client Certificate (signed by ca_rsa, 10-year validity) === */
static const unsigned char client_certificate[] = {
0x30, 0x82, 0x03, 0x89, 0x30, 0x82, 0x02, 0x71, 0xa0, 0x03, 0x02, 0x01,
0x02, 0x02, 0x14, 0x33, 0x37, 0xcd, 0x15, 0x35, 0x8b, 0x8c, 0xc7, 0xc1,
0xf0, 0x79, 0xf8, 0x9a, 0x3a, 0x11, 0x1b, 0xdb, 0xad, 0xbb, 0x60, 0x30,
0x0d, 0x06, 0x09, 0x2a, 0x86, 0x48, 0x86, 0xf7, 0x0d, 0x01, 0x01, 0x0b,
0x05, 0x00, 0x30, 0x5a, 0x31, 0x0b, 0x30, 0x09, 0x06, 0x03, 0x55, 0x04,
0x06, 0x13, 0x02, 0x43, 0x4e, 0x31, 0x10, 0x30, 0x0e, 0x06, 0x03, 0x55,
0x04, 0x08, 0x0c, 0x07, 0x42, 0x65, 0x69, 0x6a, 0x69, 0x6e, 0x67, 0x31,
0x10, 0x30, 0x0e, 0x06, 0x03, 0x55, 0x04, 0x07, 0x0c, 0x07, 0x42, 0x65,
0x69, 0x6a, 0x69, 0x6e, 0x67, 0x31, 0x11, 0x30, 0x0f, 0x06, 0x03, 0x55,
0x04, 0x0a, 0x0c, 0x08, 0x57, 0x53, 0x53, 0x2d, 0x54, 0x65, 0x73, 0x74,
0x31, 0x14, 0x30, 0x12, 0x06, 0x03, 0x55, 0x04, 0x03, 0x0c, 0x0b, 0x77,
0x73, 0x73, 0x2d, 0x74, 0x65, 0x73, 0x74, 0x2d, 0x63, 0x61, 0x30, 0x1e,
0x17, 0x0d, 0x32, 0x36, 0x30, 0x36, 0x30, 0x38, 0x30, 0x31, 0x32, 0x33,
0x32, 0x30, 0x5a, 0x17, 0x0d, 0x33, 0x36, 0x30, 0x36, 0x30, 0x35, 0x30,
0x31, 0x32, 0x33, 0x32, 0x30, 0x5a, 0x30, 0x5f, 0x31, 0x0b, 0x30, 0x09,
0x06, 0x03, 0x55, 0x04, 0x06, 0x13, 0x02, 0x43, 0x4e, 0x31, 0x10, 0x30,
0x0e, 0x06, 0x03, 0x55, 0x04, 0x08, 0x0c, 0x07, 0x42, 0x65, 0x69, 0x6a,
0x69, 0x6e, 0x67, 0x31, 0x10, 0x30, 0x0e, 0x06, 0x03, 0x55, 0x04, 0x07,
0x0c, 0x07, 0x42, 0x65, 0x69, 0x6a, 0x69, 0x6e, 0x67, 0x31, 0x11, 0x30,
0x0f, 0x06, 0x03, 0x55, 0x04, 0x0a, 0x0c, 0x08, 0x57, 0x53, 0x53, 0x2d,
0x54, 0x65, 0x73, 0x74, 0x31, 0x19, 0x30, 0x17, 0x06, 0x03, 0x55, 0x04,
0x03, 0x0c, 0x10, 0x77, 0x73, 0x73, 0x2d, 0x63, 0x6c, 0x69, 0x65, 0x6e,
0x74, 0x2e, 0x6c, 0x6f, 0x63, 0x61, 0x6c, 0x30, 0x82, 0x01, 0x22, 0x30,
0x0d, 0x06, 0x09, 0x2a, 0x86, 0x48, 0x86, 0xf7, 0x0d, 0x01, 0x01, 0x01,
0x05, 0x00, 0x03, 0x82, 0x01, 0x0f, 0x00, 0x30, 0x82, 0x01, 0x0a, 0x02,
0x82, 0x01, 0x01, 0x00, 0xde, 0xc1, 0x84, 0x50, 0x85, 0xee, 0x05, 0xce,
0xbd, 0xc0, 0x00, 0xff, 0x89, 0x5e, 0x00, 0xfe, 0xf8, 0x6e, 0x36, 0xa1,
0x9b, 0x35, 0xb7, 0x1f, 0x6c, 0x7a, 0xb6, 0xcd, 0xe7, 0x4c, 0x53, 0x5d,
0x6a, 0x59, 0x21, 0xe8, 0x3d, 0xa1, 0x03, 0x76, 0xbb, 0xc6, 0xe7, 0xa4,
0xf9, 0x2b, 0xca, 0x75, 0xdf, 0xf1, 0x60, 0xa4, 0xc9, 0xd5, 0xc7, 0xc7,
0x45, 0xf4, 0x9a, 0x1d, 0xbd, 0xfa, 0x67, 0xcc, 0x9e, 0x9a, 0xf2, 0x58,
0x48, 0x5c, 0x3a, 0xa0, 0x7b, 0x26, 0xc3, 0xef, 0x68, 0xf1, 0x52, 0xad,
0xbb, 0x11, 0x72, 0x30, 0x39, 0x3e, 0x2c, 0xdb, 0x2b, 0x36, 0xe8, 0xa9,
0xe0, 0x60, 0x41, 0xff, 0xef, 0x7e, 0xe1, 0xa2, 0x23, 0x56, 0xd8, 0x10,
0x26, 0x26, 0x7d, 0x28, 0x8b, 0x35, 0x84, 0x73, 0x9f, 0x59, 0xe2, 0x63,
0x92, 0x1e, 0xa2, 0x72, 0xfa, 0xa4, 0x57, 0xeb, 0x1a, 0x54, 0x29, 0xc9,
0x6e, 0x43, 0xbe, 0x3b, 0x0e, 0x72, 0x23, 0xe6, 0x0b, 0xb1, 0x33, 0x87,
0x19, 0x0b, 0x6e, 0x51, 0x80, 0x7f, 0xf1, 0x96, 0x8c, 0xa1, 0x09, 0xda,
0xf6, 0x44, 0xda, 0xf5, 0xbf, 0x8a, 0xef, 0xb0, 0x0a, 0xa2, 0x06, 0x70,
0x4f, 0x50, 0x62, 0xeb, 0x47, 0x95, 0xf9, 0xe8, 0xac, 0xa8, 0xdd, 0xd9,
0xc0, 0x9b, 0x28, 0xb0, 0x87, 0x95, 0xa1, 0xf5, 0xf4, 0x65, 0x7e, 0xee,
0x3a, 0x6c, 0x7f, 0xa9, 0xcc, 0xa0, 0x1b, 0xfb, 0x61, 0x30, 0x84, 0xf8,
0x21, 0xb2, 0xb5, 0x3e, 0xa6, 0x75, 0x6e, 0x18, 0xb8, 0x3c, 0x02, 0xfa,
0xca, 0xf5, 0x4a, 0x82, 0xc6, 0x92, 0x53, 0xa0, 0x64, 0x6e, 0x56, 0xf4,
0xab, 0x94, 0x22, 0x89, 0x5d, 0x34, 0x98, 0x02, 0x3a, 0xcc, 0x31, 0xdd,
0x26, 0x89, 0x6b, 0x2b, 0x9e, 0xea, 0xae, 0x0f, 0x38, 0x74, 0xea, 0x58,
0x43, 0x93, 0x7a, 0x54, 0x9d, 0x87, 0x8c, 0x29, 0x02, 0x03, 0x01, 0x00,
0x01, 0xa3, 0x42, 0x30, 0x40, 0x30, 0x1d, 0x06, 0x03, 0x55, 0x1d, 0x0e,
0x04, 0x16, 0x04, 0x14, 0xf7, 0xe6, 0x05, 0xe5, 0x4a, 0xeb, 0x0a, 0xc1,
0x3b, 0x69, 0x94, 0x0c, 0x17, 0xa4, 0x95, 0xcb, 0x01, 0x76, 0x48, 0x81,
0x30, 0x1f, 0x06, 0x03, 0x55, 0x1d, 0x23, 0x04, 0x18, 0x30, 0x16, 0x80,
0x14, 0x3b, 0x61, 0x32, 0x74, 0x0d, 0x04, 0x07, 0x2f, 0x1a, 0x96, 0x1a,
0xcb, 0xe4, 0xd3, 0xa6, 0xdd, 0xd2, 0x76, 0x77, 0xec, 0x30, 0x0d, 0x06,
0x09, 0x2a, 0x86, 0x48, 0x86, 0xf7, 0x0d, 0x01, 0x01, 0x0b, 0x05, 0x00,
0x03, 0x82, 0x01, 0x01, 0x00, 0x00, 0x88, 0xef, 0x54, 0x79, 0xa8, 0xac,
0x38, 0x62, 0x85, 0xea, 0xac, 0x7b, 0x6d, 0x06, 0x45, 0x99, 0x00, 0xa3,
0xeb, 0xc0, 0x3f, 0xfa, 0x42, 0x0d, 0x9f, 0x52, 0xe6, 0x4c, 0x3b, 0xb1,
0x05, 0x74, 0x23, 0xaa, 0x49, 0xc9, 0xc9, 0x74, 0xf0, 0x21, 0xe9, 0x6d,
0xe7, 0x2a, 0x99, 0x3a, 0xb1, 0xbe, 0x8e, 0x21, 0x08, 0xda, 0x33, 0xbc,
0x08, 0xfb, 0x82, 0x3e, 0xff, 0xd3, 0x47, 0xbd, 0x4d, 0x2e, 0xfa, 0xab,
0x9d, 0x62, 0x53, 0x5a, 0x81, 0x32, 0x90, 0x5e, 0x74, 0xa1, 0x64, 0x39,
0xb0, 0x92, 0xce, 0xcf, 0x1b, 0x6f, 0x80, 0x59, 0x53, 0x5a, 0xfd, 0xf2,
0x26, 0x63, 0x9d, 0x09, 0xaa, 0xb9, 0xe8, 0xfe, 0x19, 0xc6, 0x62, 0xd8,
0x8d, 0x0a, 0x2a, 0xd1, 0xe6, 0x85, 0xcb, 0x87, 0x20, 0x15, 0x4e, 0xae,
0x36, 0xcc, 0xa6, 0xe7, 0xda, 0xba, 0x5c, 0x6a, 0x5f, 0xef, 0x49, 0x99,
0x27, 0x36, 0xba, 0x8d, 0xd7, 0x63, 0x41, 0x71, 0x21, 0x50, 0x01, 0xab,
0xc8, 0x2c, 0xcc, 0x00, 0xd3, 0x2a, 0x9a, 0x02, 0x91, 0x80, 0xd2, 0xf0,
0xbf, 0x73, 0x33, 0x4d, 0xa1, 0x5b, 0x25, 0x23, 0xee, 0xa8, 0x37, 0x52,
0xbe, 0xc6, 0x3c, 0xb3, 0x65, 0x2d, 0xab, 0x05, 0x78, 0x9a, 0x20, 0xf1,
0x37, 0x1f, 0xc1, 0x75, 0xc1, 0xa9, 0x76, 0x7c, 0xf0, 0xa6, 0x65, 0x70,
0x30, 0x91, 0xe4, 0xc1, 0xaf, 0xf8, 0x3a, 0xe9, 0xc3, 0x35, 0x1c, 0xd8,
0xe4, 0x4a, 0x16, 0xb1, 0x84, 0x09, 0xa0, 0x9a, 0x70, 0xdf, 0xc8, 0x3d,
0xfd, 0x6e, 0x98, 0x0d, 0x8e, 0xde, 0x7a, 0xbc, 0xf8, 0x69, 0xaf, 0x42,
0x00, 0xd7, 0x26, 0x9c, 0xd9, 0xc1, 0xb5, 0x1d, 0x28, 0xe1, 0x0e, 0x46,
0x28, 0xe9, 0x3c, 0x77, 0xde, 0x33, 0x14, 0xad, 0x4f, 0x4a, 0xc3, 0x24,
0xc2, 0x6e, 0xcb, 0x17, 0x51, 0x83, 0x71, 0x6b, 0x7d
};

/* === Client Private Key (RSA 2048-bit, PKCS#8 DER) === */
static const unsigned char client_private_key[] = {
0x30, 0x82, 0x04, 0xbd, 0x02, 0x01, 0x00, 0x30, 0x0d, 0x06, 0x09, 0x2a,
0x86, 0x48, 0x86, 0xf7, 0x0d, 0x01, 0x01, 0x01, 0x05, 0x00, 0x04, 0x82,
0x04, 0xa7, 0x30, 0x82, 0x04, 0xa3, 0x02, 0x01, 0x00, 0x02, 0x82, 0x01,
0x01, 0x00, 0xde, 0xc1, 0x84, 0x50, 0x85, 0xee, 0x05, 0xce, 0xbd, 0xc0,
0x00, 0xff, 0x89, 0x5e, 0x00, 0xfe, 0xf8, 0x6e, 0x36, 0xa1, 0x9b, 0x35,
0xb7, 0x1f, 0x6c, 0x7a, 0xb6, 0xcd, 0xe7, 0x4c, 0x53, 0x5d, 0x6a, 0x59,
0x21, 0xe8, 0x3d, 0xa1, 0x03, 0x76, 0xbb, 0xc6, 0xe7, 0xa4, 0xf9, 0x2b,
0xca, 0x75, 0xdf, 0xf1, 0x60, 0xa4, 0xc9, 0xd5, 0xc7, 0xc7, 0x45, 0xf4,
0x9a, 0x1d, 0xbd, 0xfa, 0x67, 0xcc, 0x9e, 0x9a, 0xf2, 0x58, 0x48, 0x5c,
0x3a, 0xa0, 0x7b, 0x26, 0xc3, 0xef, 0x68, 0xf1, 0x52, 0xad, 0xbb, 0x11,
0x72, 0x30, 0x39, 0x3e, 0x2c, 0xdb, 0x2b, 0x36, 0xe8, 0xa9, 0xe0, 0x60,
0x41, 0xff, 0xef, 0x7e, 0xe1, 0xa2, 0x23, 0x56, 0xd8, 0x10, 0x26, 0x26,
0x7d, 0x28, 0x8b, 0x35, 0x84, 0x73, 0x9f, 0x59, 0xe2, 0x63, 0x92, 0x1e,
0xa2, 0x72, 0xfa, 0xa4, 0x57, 0xeb, 0x1a, 0x54, 0x29, 0xc9, 0x6e, 0x43,
0xbe, 0x3b, 0x0e, 0x72, 0x23, 0xe6, 0x0b, 0xb1, 0x33, 0x87, 0x19, 0x0b,
0x6e, 0x51, 0x80, 0x7f, 0xf1, 0x96, 0x8c, 0xa1, 0x09, 0xda, 0xf6, 0x44,
0xda, 0xf5, 0xbf, 0x8a, 0xef, 0xb0, 0x0a, 0xa2, 0x06, 0x70, 0x4f, 0x50,
0x62, 0xeb, 0x47, 0x95, 0xf9, 0xe8, 0xac, 0xa8, 0xdd, 0xd9, 0xc0, 0x9b,
0x28, 0xb0, 0x87, 0x95, 0xa1, 0xf5, 0xf4, 0x65, 0x7e, 0xee, 0x3a, 0x6c,
0x7f, 0xa9, 0xcc, 0xa0, 0x1b, 0xfb, 0x61, 0x30, 0x84, 0xf8, 0x21, 0xb2,
0xb5, 0x3e, 0xa6, 0x75, 0x6e, 0x18, 0xb8, 0x3c, 0x02, 0xfa, 0xca, 0xf5,
0x4a, 0x82, 0xc6, 0x92, 0x53, 0xa0, 0x64, 0x6e, 0x56, 0xf4, 0xab, 0x94,
0x22, 0x89, 0x5d, 0x34, 0x98, 0x02, 0x3a, 0xcc, 0x31, 0xdd, 0x26, 0x89,
0x6b, 0x2b, 0x9e, 0xea, 0xae, 0x0f, 0x38, 0x74, 0xea, 0x58, 0x43, 0x93,
0x7a, 0x54, 0x9d, 0x87, 0x8c, 0x29, 0x02, 0x03, 0x01, 0x00, 0x01, 0x02,
0x82, 0x01, 0x00, 0x23, 0xd5, 0xbf, 0xe2, 0x70, 0x59, 0x45, 0x47, 0xe8,
0x10, 0xae, 0x58, 0x6d, 0x91, 0xd8, 0xd9, 0x2b, 0xc0, 0x17, 0x3b, 0xd2,
0x4b, 0x46, 0xe5, 0x60, 0x3f, 0x31, 0x8f, 0x58, 0x49, 0x58, 0x13, 0xec,
0x1a, 0xe0, 0xb0, 0x8a, 0xd1, 0x8f, 0x4c, 0x17, 0x93, 0x3d, 0x0a, 0xb6,
0x27, 0x0c, 0x50, 0x00, 0x31, 0xc5, 0x99, 0x5c, 0xfa, 0xee, 0x43, 0xa9,
0x86, 0x5b, 0x10, 0xb3, 0xd2, 0x47, 0xc6, 0x8c, 0x31, 0x63, 0x11, 0x3e,
0xba, 0xcf, 0x97, 0xa7, 0x98, 0x29, 0xe7, 0x26, 0xdb, 0xc3, 0xb0, 0x3d,
0x2a, 0xe6, 0x52, 0xc9, 0xb2, 0xad, 0xe6, 0xa8, 0x42, 0x12, 0x15, 0xda,
0x09, 0xc2, 0x34, 0x59, 0x23, 0xf1, 0x4a, 0x73, 0x22, 0xf2, 0x69, 0x4e,
0xa9, 0xdc, 0x72, 0x9c, 0x4a, 0x84, 0xbf, 0x51, 0x00, 0x55, 0xc2, 0x2c,
0xec, 0x8e, 0xb7, 0xae, 0x88, 0xa7, 0xb8, 0x23, 0xa9, 0x2c, 0x7b, 0x75,
0x4e, 0x3c, 0x13, 0x9d, 0xe0, 0x26, 0x73, 0x20, 0x48, 0xb5, 0x50, 0x9c,
0x0f, 0x44, 0x07, 0xce, 0x6b, 0x0d, 0x7a, 0x8a, 0xb4, 0x8a, 0xd3, 0x62,
0x30, 0xcd, 0x84, 0x69, 0xb7, 0x62, 0x4e, 0x55, 0xa6, 0x15, 0xce, 0x89,
0xc5, 0x01, 0x24, 0xa7, 0x27, 0x3b, 0xc5, 0xb8, 0xe8, 0xd3, 0x9b, 0xe4,
0x2a, 0xfa, 0xb3, 0x62, 0xe9, 0x2a, 0x39, 0x5c, 0xe3, 0xa1, 0x81, 0x47,
0xa4, 0xda, 0xa0, 0x3c, 0x4d, 0x42, 0x6e, 0x19, 0x55, 0x78, 0x61, 0x29,
0xe2, 0x18, 0xe5, 0x65, 0x48, 0x57, 0xa9, 0xa8, 0x83, 0x7f, 0x40, 0xaa,
0x6d, 0x3a, 0x1f, 0x80, 0xb6, 0x26, 0x70, 0xa4, 0x93, 0x47, 0xd0, 0x8d,
0xa5, 0x8f, 0xa1, 0x1c, 0x3d, 0x23, 0xf8, 0xf9, 0x7a, 0xaf, 0x8b, 0xd8,
0x19, 0x84, 0xae, 0xa3, 0xe5, 0x23, 0x6b, 0x5d, 0xfd, 0x1c, 0x68, 0xc7,
0xde, 0x93, 0xea, 0xe2, 0x9e, 0xce, 0xfd, 0x02, 0x81, 0x81, 0x00, 0xf4,
0x4d, 0x4f, 0xa5, 0x07, 0xad, 0xba, 0x9a, 0xbf, 0xce, 0xed, 0xce, 0xd3,
0xca, 0x0a, 0xfe, 0xb6, 0x68, 0x5b, 0x91, 0x71, 0x34, 0x8b, 0x2e, 0xe9,
0x39, 0xef, 0x84, 0x3a, 0x3c, 0xdb, 0x11, 0x8b, 0xd9, 0x7f, 0x8e, 0xbf,
0x49, 0x0e, 0xb9, 0x65, 0x53, 0xac, 0xc5, 0xe8, 0x3a, 0x7d, 0xc3, 0x39,
0x0b, 0x8e, 0xc1, 0x85, 0xd7, 0x22, 0x15, 0xdc, 0x59, 0x61, 0x85, 0xb9,
0xc2, 0x66, 0xb3, 0x99, 0xc3, 0x49, 0x09, 0xc4, 0xa1, 0x9c, 0x0d, 0x18,
0x7d, 0xd4, 0x06, 0x37, 0x3c, 0x5d, 0xa9, 0xe7, 0x75, 0xca, 0x94, 0x0c,
0x25, 0x63, 0xe3, 0xef, 0xee, 0x8e, 0x79, 0xdb, 0x7d, 0x35, 0xd5, 0x0e,
0x05, 0x55, 0x3d, 0x80, 0x69, 0xac, 0x06, 0xe3, 0xfa, 0x2b, 0xe2, 0xec,
0xdb, 0xb0, 0x3c, 0x59, 0x9f, 0x04, 0x5c, 0x49, 0x3b, 0x13, 0x71, 0x74,
0xa0, 0xc1, 0xf4, 0xa1, 0x6f, 0xe0, 0x13, 0x02, 0x81, 0x81, 0x00, 0xe9,
0x6c, 0x17, 0x45, 0xf8, 0xb0, 0x8a, 0x87, 0x60, 0x17, 0x11, 0xf1, 0xa3,
0x7e, 0xb8, 0x8c, 0xbd, 0x0e, 0x6f, 0x34, 0x22, 0xcd, 0xa8, 0x12, 0xe8,
0x33, 0xfc, 0xa1, 0x27, 0xc7, 0x0c, 0xed, 0xc0, 0x4f, 0x15, 0x7e, 0xde,
0x58, 0xfd, 0x5f, 0x5b, 0x1c, 0x60, 0x19, 0xca, 0x76, 0xc3, 0x9f, 0xf1,
0xac, 0x9e, 0xf3, 0x75, 0xb3, 0x02, 0xd6, 0x48, 0x0d, 0x51, 0xc2, 0xe6,
0x28, 0x6d, 0x7b, 0xc5, 0xe6, 0x40, 0x71, 0xd9, 0x14, 0x07, 0x2e, 0x88,
0x3d, 0xb9, 0x3d, 0xb9, 0x37, 0x0c, 0xd6, 0xd5, 0x4f, 0xa8, 0xcb, 0xe8,
0xf1, 0x71, 0xcf, 0x04, 0x58, 0x91, 0x0c, 0x23, 0xfb, 0x32, 0x5e, 0x0e,
0x6a, 0x5f, 0x7a, 0xa1, 0xc2, 0x1a, 0x3c, 0x3b, 0x8f, 0x7d, 0xcb, 0x39,
0x92, 0x9c, 0xf1, 0x71, 0x27, 0x41, 0xdb, 0xe3, 0x31, 0xe9, 0xfd, 0x4f,
0x82, 0x91, 0xae, 0xe9, 0x2f, 0x42, 0x53, 0x02, 0x81, 0x80, 0x4f, 0x52,
0x56, 0xdc, 0xcf, 0x9c, 0x71, 0xed, 0x52, 0xff, 0xfe, 0x28, 0xdc, 0x8d,
0x4a, 0x7a, 0x9f, 0x81, 0x4c, 0xd1, 0xf1, 0x7e, 0xcc, 0xfe, 0x43, 0x4d,
0xc3, 0x5e, 0x1c, 0x86, 0xab, 0xde, 0x8b, 0x98, 0xe8, 0x18, 0xd2, 0x35,
0x07, 0x69, 0xdc, 0xe3, 0x89, 0x42, 0x8c, 0xff, 0x88, 0xdb, 0xfd, 0x46,
0xaa, 0x68, 0x5d, 0x6b, 0x97, 0xae, 0x9f, 0x68, 0x0a, 0x09, 0x20, 0x62,
0x65, 0x74, 0x45, 0x25, 0xaa, 0x2e, 0x58, 0xc0, 0xdc, 0x69, 0x48, 0x1d,
0x7a, 0xdd, 0x35, 0xcc, 0x0c, 0xe1, 0x60, 0xbc, 0xd7, 0x34, 0xb0, 0xa8,
0xe7, 0x41, 0x18, 0x23, 0x4d, 0xf1, 0x74, 0xf9, 0xb7, 0xa3, 0xe0, 0xb4,
0x8c, 0x93, 0xb6, 0x81, 0x19, 0x10, 0xf7, 0xae, 0xbf, 0xd7, 0x23, 0x6e,
0xc5, 0x4f, 0x23, 0x0e, 0x45, 0x9d, 0x2d, 0x4d, 0xd8, 0x27, 0x4b, 0x65,
0xf2, 0xf3, 0xda, 0x02, 0xf8, 0x2f, 0x02, 0x81, 0x81, 0x00, 0xcb, 0xb1,
0x5d, 0xa5, 0xdb, 0xdd, 0x03, 0x26, 0x1b, 0x7e, 0x46, 0x54, 0x5d, 0x5e,
0x29, 0xe1, 0xf6, 0xe0, 0xef, 0xbd, 0xc9, 0x59, 0x3a, 0x00, 0x35, 0xcd,
0x97, 0xf9, 0x71, 0xe2, 0xcb, 0xaf, 0x75, 0x90, 0x0d, 0xac, 0x06, 0x90,
0x15, 0x9a, 0xee, 0xc1, 0x16, 0x43, 0xab, 0x60, 0x74, 0x59, 0xd0, 0xe5,
0xd8, 0x57, 0x90, 0x30, 0x44, 0x9b, 0x85, 0x88, 0xc9, 0xfe, 0x90, 0x26,
0x5b, 0x54, 0x15, 0x60, 0x56, 0x80, 0x82, 0xf4, 0x6d, 0x47, 0xf7, 0xf0,
0x15, 0x04, 0x7d, 0xea, 0x42, 0x33, 0xff, 0x35, 0x62, 0x91, 0x7e, 0x97,
0xa3, 0xbf, 0x09, 0x85, 0xd8, 0x1d, 0x86, 0x10, 0xa0, 0xe5, 0x5f, 0x23,
0x08, 0x6a, 0xd5, 0x59, 0xb2, 0xd7, 0x39, 0x0a, 0x80, 0xb5, 0xa5, 0x6a,
0x01, 0xb6, 0xd8, 0x0d, 0x6f, 0xf5, 0x58, 0x8f, 0xa8, 0x27, 0x3b, 0x09,
0x2f, 0xe4, 0x38, 0xec, 0xda, 0xad, 0x02, 0x81, 0x80, 0x7c, 0x6a, 0xdf,
0x03, 0xeb, 0xf4, 0x34, 0x3b, 0xe0, 0xa3, 0xa8, 0xfa, 0x5c, 0xac, 0x37,
0x53, 0x35, 0xf0, 0x7d, 0x21, 0xd5, 0x98, 0x56, 0x43, 0xa5, 0x1f, 0xd7,
0xe7, 0xdb, 0xeb, 0x55, 0xe7, 0x26, 0x05, 0x09, 0xd8, 0xeb, 0xdd, 0x7b,
0xda, 0x5f, 0xbd, 0xef, 0xb1, 0xfb, 0xe8, 0x02, 0x7d, 0x98, 0x01, 0xf8,
0x7b, 0x05, 0x7d, 0x2f, 0xdd, 0xb9, 0x5e, 0xc7, 0xe1, 0x98, 0x75, 0xe5,
0x74, 0xc3, 0x51, 0x5d, 0xe3, 0x02, 0x80, 0x46, 0x1c, 0x6b, 0x79, 0x87,
0x64, 0xef, 0x47, 0x23, 0x49, 0x52, 0x5a, 0x93, 0x69, 0xaa, 0x82, 0x59,
0x86, 0xab, 0x66, 0x43, 0x52, 0xa5, 0x4a, 0x42, 0x5b, 0xd6, 0x55, 0x38,
0xfe, 0x0e, 0x33, 0x26, 0x31, 0x48, 0x4d, 0xcd, 0x74, 0xea, 0xee, 0xc0,
0x34, 0x4b, 0x05, 0x06, 0xc8, 0x73, 0xec, 0x2b, 0x46, 0x94, 0x0e, 0xbd,
0x86, 0x2c, 0xc5, 0x86, 0xbd
};

#endif /* TLS_CERTIFICATES_H */
```
